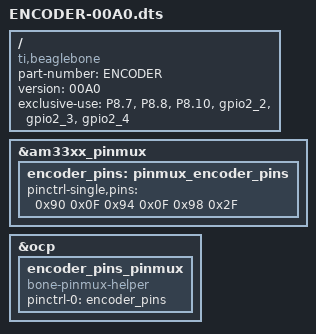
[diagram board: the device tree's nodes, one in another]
/dts-v1/;
/plugin/;

/ {
	compatible = "ti,beaglebone", "ti,beaglebone-black", "ti,beaglebone-green";

	part-number = "ENCODER";
	version = "00A0";

	exclusive-use =

		"P8.7",
		"P8.8",
		"P8.10",
		"gpio2_2",
		"gpio2_3",
		"gpio2_4";

	fragment@0 {
		target = <&am33xx_pinmux>;
		__overlay__ {
			encoder_pins: pinmux_encoder_pins {
				pinctrl-single,pins = <
					0x90 0x0F     /* P8.7 */
					0x94 0x0F     /* P8.8 */
					0x98 0x2F     /* P8.10 */
				>;
			};
		};
	};

	fragment@1 {
		target = <&ocp>;
		__overlay__ {
			encoder_pins_pinmux {
                	compatible = "bone-pinmux-helper";
                	status = "okay";
                	pinctrl-names = "default";
                	pinctrl-0 = <&encoder_pins>;
            		};
		};
	};

};
